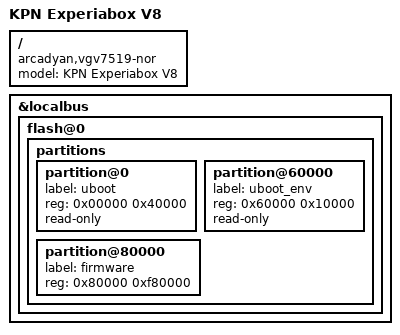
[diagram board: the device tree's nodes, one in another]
/dts-v1/;

#include "VGV7519.dtsi"

/ {
	compatible = "arcadyan,vgv7519-nor", "arcadyan,vgv7519", "lantiq,xway", "lantiq,vr9";
	model = "KPN Experiabox V8";
};

&localbus {
	flash@0 {
		partitions {
			partition@0 {
				label = "uboot";
				reg = <0x00000 0x40000>;
				read-only;
			};
			partition@60000 {
				label = "uboot_env";
				reg = <0x60000 0x10000>;
				read-only;
			};
			partition@80000 {
				label = "firmware";
				reg = <0x80000 0xf80000>;
			};
		};
	};
};
